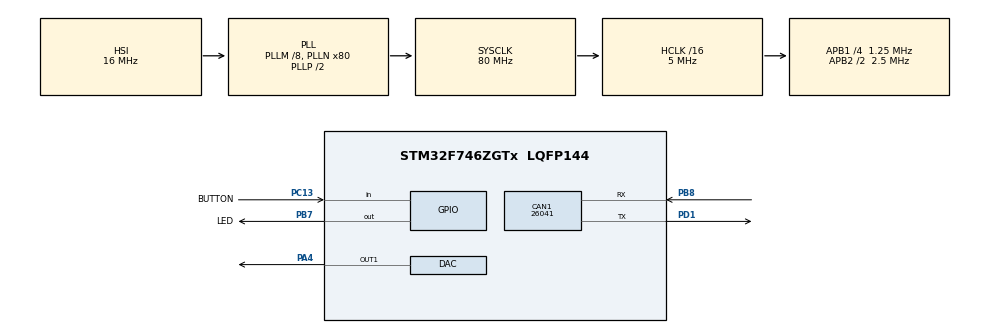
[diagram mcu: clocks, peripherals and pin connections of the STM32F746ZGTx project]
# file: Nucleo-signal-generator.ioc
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CAN1.BS2=CAN_BS2_1TQ
CAN1.CalculateBaudRate=26041
CAN1.CalculateTimeBit=38400
CAN1.CalculateTimeQuantum=12800.0
Mcu.Family=STM32F7
Mcu.Name=STM32F746ZGTx
Mcu.Package=LQFP144
NVIC.CAN1_RX0_IRQn=true\:0\:0\:false\:false\:true\:true\:true\:true
NVIC.PriorityGroup=NVIC_PRIORITYGROUP_4
PA4.Signal=COMP_DAC1_group
PB7.GPIO_Label=LED
PB7.Signal=GPIO_Output
PB8.Mode=CAN_Activate
PB8.Signal=CAN1_RX
PC13.GPIO_Label=BUTTON
PC13.Signal=GPIO_Input
PD1.Mode=CAN_Activate
PD1.Signal=CAN1_TX
ProjectManager.HeapSize=0x200
ProjectManager.StackSize=0x400
ProjectManager.TargetToolchain=STM32CubeIDE
RCC.AHBCLKDivider=RCC_SYSCLK_DIV16
RCC.AHBFreq_Value=5000000
RCC.APB1CLKDivider=RCC_HCLK_DIV4
RCC.APB1Freq_Value=1250000
RCC.APB1TimFreq_Value=2500000
RCC.APB2CLKDivider=RCC_HCLK_DIV2
RCC.APB2Freq_Value=2500000
RCC.APB2TimFreq_Value=5000000
RCC.CortexFreq_Value=5000000
RCC.HCLKFreq_Value=5000000
RCC.HSE_VALUE=25000000
RCC.HSI_VALUE=16000000
RCC.LSE_VALUE=32768
RCC.PLLM=8
RCC.PLLN=80
RCC.SYSCLKFreq_VALUE=80000000
RCC.SYSCLKSource=RCC_SYSCLKSOURCE_PLLCLK
RCC.USBFreq_Value=80000000
RCC.VCOOutputFreq_Value=160000000
SH.COMP_DAC1_group.0=DAC_OUT1,DAC_OUT1
TIM1.Prescaler=5-1
VP_TIM1_VS_ClockSourceINT.Mode=Internal
board=custom

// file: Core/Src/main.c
/* USER CODE BEGIN Header */
/**
  ******************************************************************************
  * @file           : main.c
  * @brief          : Main program body
  ******************************************************************************
  * @attention
  *
  * Copyright (c) 2022 STMicroelectronics.
  * All rights reserved.
  *
  * This software is licensed under terms that can be found in the LICENSE file
  * in the root directory of this software component.
  * If no LICENSE file comes with this software, it is provided AS-IS.
  *
  ******************************************************************************
  */
/* USER CODE END Header */
#include "main.h"

/* USER CODE BEGIN Includes */
#include <math.h>
/* USER CODE END Includes */

 CAN_HandleTypeDef hcan1;

DAC_HandleTypeDef hdac;

TIM_HandleTypeDef htim1;

void SystemClock_Config(void);
static void MX_GPIO_Init(void);
static void MX_CAN1_Init(void);
static void MX_DAC_Init(void);
static void MX_TIM1_Init(void);

/* USER CODE BEGIN 0 */
void delay_us (uint16_t us)
{
	__HAL_TIM_SET_COUNTER(&htim1,0);  // set the counter value a 0
	while (__HAL_TIM_GET_COUNTER(&htim1) < us);  // wait for the counter to reach the us input in the parameter
}
/* USER CODE END 0 */

int main(void)
{

  /* MCU Configuration--------------------------------------------------------*/

  /* Reset of all peripherals, Initializes the Flash interface and the Systick. */
  HAL_Init();

  /* Configure the system clock */
  SystemClock_Config();

  /* Initialize all configured peripherals */
  MX_GPIO_Init();
  MX_CAN1_Init();
  MX_DAC_Init();
  MX_TIM1_Init();
  /* USER CODE BEGIN 2 */
  HAL_TIM_Base_Start(&htim1);
    HAL_DAC_Start(&hdac, DAC_CHANNEL_1);

    uint32_t i = 0;

    uint32_t sampleRate = 100; //controls number of samples in 1 sine wave, more samples = smoother

    uint32_t waitTime = 100; //microsecond delay between each sample. frequency in Hz = 1000 / (sample rate * wait time)
  /* USER CODE END 2 */

  /* Infinite loop */
    while (1)
    {

    /* USER CODE BEGIN 3 */
  	DAC1->DHR12R1 = ((sin((i % sampleRate) * 2 * M_PI / sampleRate) + 1)*(4094/2));
  	i++;
  	delay_us(waitTime);
    }
  /* USER CODE END 3 */
}

void SystemClock_Config(void)
{
  RCC_OscInitTypeDef RCC_OscInitStruct = {0};
  RCC_ClkInitTypeDef RCC_ClkInitStruct = {0};

  /** Configure the main internal regulator output voltage
  */
  __HAL_RCC_PWR_CLK_ENABLE();
  __HAL_PWR_VOLTAGESCALING_CONFIG(PWR_REGULATOR_VOLTAGE_SCALE3);

  /** Initializes the RCC Oscillators according to the specified parameters
  * in the RCC_OscInitTypeDef structure.
  */
  RCC_OscInitStruct.OscillatorType = RCC_OSCILLATORTYPE_HSI;
  RCC_OscInitStruct.HSIState = RCC_HSI_ON;
  RCC_OscInitStruct.HSICalibrationValue = RCC_HSICALIBRATION_DEFAULT;
  RCC_OscInitStruct.PLL.PLLState = RCC_PLL_ON;
  RCC_OscInitStruct.PLL.PLLSource = RCC_PLLSOURCE_HSI;
  RCC_OscInitStruct.PLL.PLLM = 8;
  RCC_OscInitStruct.PLL.PLLN = 80;
  RCC_OscInitStruct.PLL.PLLP = RCC_PLLP_DIV2;
  RCC_OscInitStruct.PLL.PLLQ = 2;
  if (HAL_RCC_OscConfig(&RCC_OscInitStruct) != HAL_OK)
  {
    Error_Handler();
  }

  /** Initializes the CPU, AHB and APB buses clocks
  */
  RCC_ClkInitStruct.ClockType = RCC_CLOCKTYPE_HCLK|RCC_CLOCKTYPE_SYSCLK
                              |RCC_CLOCKTYPE_PCLK1|RCC_CLOCKTYPE_PCLK2;
  RCC_ClkInitStruct.SYSCLKSource = RCC_SYSCLKSOURCE_PLLCLK;
  RCC_ClkInitStruct.AHBCLKDivider = RCC_SYSCLK_DIV16;
  RCC_ClkInitStruct.APB1CLKDivider = RCC_HCLK_DIV4;
  RCC_ClkInitStruct.APB2CLKDivider = RCC_HCLK_DIV2;

  if (HAL_RCC_ClockConfig(&RCC_ClkInitStruct, FLASH_LATENCY_0) != HAL_OK)
  {
    Error_Handler();
  }
}

static void MX_CAN1_Init(void)
{

  hcan1.Instance = CAN1;
  hcan1.Init.Prescaler = 16;
  hcan1.Init.Mode = CAN_MODE_NORMAL;
  hcan1.Init.SyncJumpWidth = CAN_SJW_1TQ;
  hcan1.Init.TimeSeg1 = CAN_BS1_1TQ;
  hcan1.Init.TimeSeg2 = CAN_BS2_1TQ;
  hcan1.Init.TimeTriggeredMode = DISABLE;
  hcan1.Init.AutoBusOff = DISABLE;
  hcan1.Init.AutoWakeUp = DISABLE;
  hcan1.Init.AutoRetransmission = DISABLE;
  hcan1.Init.ReceiveFifoLocked = DISABLE;
  hcan1.Init.TransmitFifoPriority = DISABLE;
  if (HAL_CAN_Init(&hcan1) != HAL_OK)
  {
    Error_Handler();
  }

}

static void MX_DAC_Init(void)
{

  DAC_ChannelConfTypeDef sConfig = {0};

  /** DAC Initialization
  */
  hdac.Instance = DAC;
  if (HAL_DAC_Init(&hdac) != HAL_OK)
  {
    Error_Handler();
  }

  /** DAC channel OUT1 config
  */
  sConfig.DAC_Trigger = DAC_TRIGGER_NONE;
  sConfig.DAC_OutputBuffer = DAC_OUTPUTBUFFER_ENABLE;
  if (HAL_DAC_ConfigChannel(&hdac, &sConfig, DAC_CHANNEL_1) != HAL_OK)
  {
    Error_Handler();
  }

}

static void MX_TIM1_Init(void)
{

  TIM_ClockConfigTypeDef sClockSourceConfig = {0};
  TIM_MasterConfigTypeDef sMasterConfig = {0};

  htim1.Instance = TIM1;
  htim1.Init.Prescaler = 5-1;
  htim1.Init.CounterMode = TIM_COUNTERMODE_UP;
  htim1.Init.Period = 65535;
  htim1.Init.ClockDivision = TIM_CLOCKDIVISION_DIV1;
  htim1.Init.RepetitionCounter = 0;
  htim1.Init.AutoReloadPreload = TIM_AUTORELOAD_PRELOAD_DISABLE;
  if (HAL_TIM_Base_Init(&htim1) != HAL_OK)
  {
    Error_Handler();
  }
  sClockSourceConfig.ClockSource = TIM_CLOCKSOURCE_INTERNAL;
  if (HAL_TIM_ConfigClockSource(&htim1, &sClockSourceConfig) != HAL_OK)
  {
    Error_Handler();
  }
  sMasterConfig.MasterOutputTrigger = TIM_TRGO_RESET;
  sMasterConfig.MasterOutputTrigger2 = TIM_TRGO2_RESET;
  sMasterConfig.MasterSlaveMode = TIM_MASTERSLAVEMODE_DISABLE;
  if (HAL_TIMEx_MasterConfigSynchronization(&htim1, &sMasterConfig) != HAL_OK)
  {
    Error_Handler();
  }

}

static void MX_GPIO_Init(void)
{
  GPIO_InitTypeDef GPIO_InitStruct = {0};

  /* GPIO Ports Clock Enable */
  __HAL_RCC_GPIOC_CLK_ENABLE();
  __HAL_RCC_GPIOA_CLK_ENABLE();
  __HAL_RCC_GPIOD_CLK_ENABLE();
  __HAL_RCC_GPIOB_CLK_ENABLE();

  /*Configure GPIO pin Output Level */
  HAL_GPIO_WritePin(LED_GPIO_Port, LED_Pin, GPIO_PIN_RESET);

  /*Configure GPIO pin : BUTTON_Pin */
  GPIO_InitStruct.Pin = BUTTON_Pin;
  GPIO_InitStruct.Mode = GPIO_MODE_INPUT;
  GPIO_InitStruct.Pull = GPIO_NOPULL;
  HAL_GPIO_Init(BUTTON_GPIO_Port, &GPIO_InitStruct);

  /*Configure GPIO pin : LED_Pin */
  GPIO_InitStruct.Pin = LED_Pin;
  GPIO_InitStruct.Mode = GPIO_MODE_OUTPUT_PP;
  GPIO_InitStruct.Pull = GPIO_NOPULL;
  GPIO_InitStruct.Speed = GPIO_SPEED_FREQ_LOW;
  HAL_GPIO_Init(LED_GPIO_Port, &GPIO_InitStruct);

}

void Error_Handler(void)
{
  __disable_irq();
  while (1)
  {
  }
}
